AUTOSAR XML (schema 4-0-3)
standard types defined: uint8, Boolean, UInt16, UInt32, UInt8
package /AUTOSAR_Platform/DataConstrs
  range DC_Boolean: raw 0..1
  range DC_UInt16: raw 0..65535
  range DC_UInt8: raw 0..255
package /PATAC/Facility/DataTypes/Implementation
  compu method COMPU_Boolean: 0=FALSE, 1=TRUE
  unit NoUnit: factor-si-to-unit=1, offset-si-to-unit=0
package /PATAC/MSM/ComponentTypes
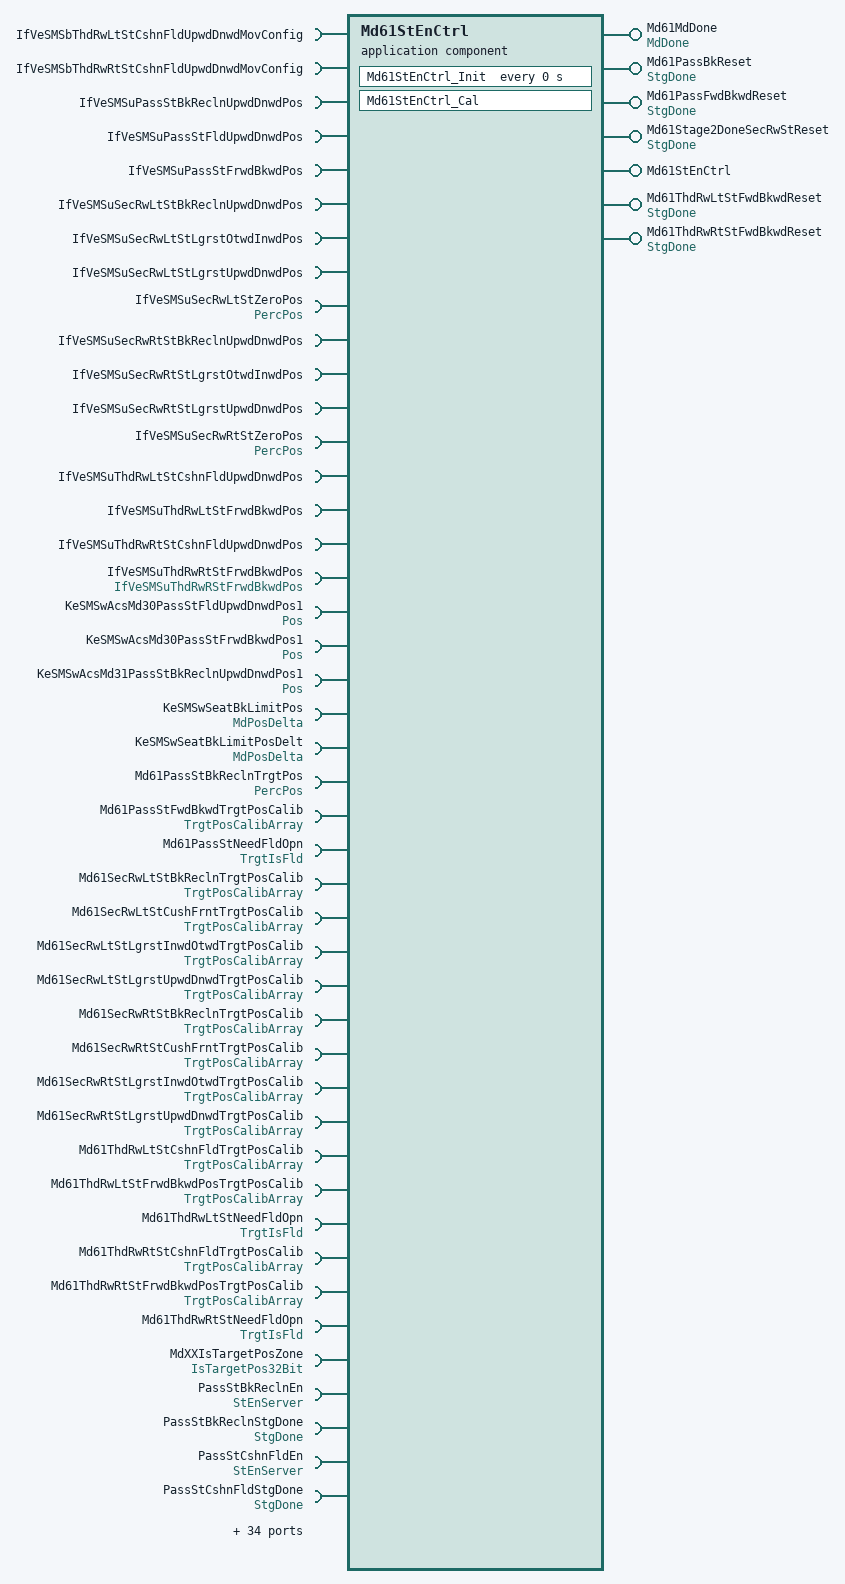
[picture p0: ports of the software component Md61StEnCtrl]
  application sw component type Md61StEnCtrl
    7 x provide port:
      Md61MdDone: nonqueued-sender-com-spec{data-element=MdDone/Val, init-value=0}, provided-interface=MdDone
      Md61PassBkReset: nonqueued-sender-com-spec{data-element=StgDone/Val, init-value=0}, provided-interface=StgDone
      Md61PassFwdBkwdReset: nonqueued-sender-com-spec{data-element=StgDone/Val, init-value=0}, provided-interface=StgDone
      Md61Stage2DoneSecRwStReset: nonqueued-sender-com-spec{data-element=StgDone/Val, init-value=0}, provided-interface=StgDone
      Md61StEnCtrl: server-com-spec{operation=Cal, queue-length=1}, provided-interface=Md61StEnCtrl
      Md61ThdRwLtStFwdBkwdReset: nonqueued-sender-com-spec{data-element=StgDone/Val, init-value=0}, provided-interface=StgDone
      Md61ThdRwRtStFwdBkwdReset: nonqueued-sender-com-spec{data-element=StgDone/Val, init-value=0}, provided-interface=StgDone
    78 x require port:
      IfVeSMSbThdRwLtStCshnFldUpwdDnwdMovConfig: nonqueued-receiver-com-spec{data-element=IfVeSMSbThdRwLtStCshnFldUpwdDnwdMovConfig/Val, filter=data-filter-type=ALWAYS, init-value=0}, required-interface=IfVeSMSbThdRwLtStCshnFldUpwdDnwdMovConfig
      IfVeSMSbThdRwRtStCshnFldUpwdDnwdMovConfig: nonqueued-receiver-com-spec{data-element=IfVeSMSbThdRwRtStCshnFldUpwdDnwdMovConfig/Val, filter=data-filter-type=ALWAYS, init-value=0}, required-interface=IfVeSMSbThdRwRtStCshnFldUpwdDnwdMovConfig
      IfVeSMSuPassStBkReclnUpwdDnwdPos: nonqueued-receiver-com-spec{data-element=IfVeSMSuPassStBkReclnUpwdDnwdPos/Val, filter=data-filter-type=ALWAYS, init-value=0}, required-interface=IfVeSMSuPassStBkReclnUpwdDnwdPos
      IfVeSMSuPassStFldUpwdDnwdPos: nonqueued-receiver-com-spec{data-element=IfVeSMSuPassStFldUpwdDnwdPos/Val, filter=data-filter-type=ALWAYS, init-value=0}, required-interface=IfVeSMSuPassStFldUpwdDnwdPos
      IfVeSMSuPassStFrwdBkwdPos: nonqueued-receiver-com-spec{data-element=IfVeSMSuPassStFrwdBkwdPos/Val, filter=data-filter-type=ALWAYS, init-value=0}, required-interface=IfVeSMSuPassStFrwdBkwdPos
      IfVeSMSuSecRwLtStBkReclnUpwdDnwdPos: nonqueued-receiver-com-spec{data-element=IfVeSMSuSecRwLtStBkReclnUpwdDnwdPos/Val, filter=data-filter-type=ALWAYS, init-value=0}, required-interface=IfVeSMSuSecRwLtStBkReclnUpwdDnwdPos
      IfVeSMSuSecRwLtStLgrstOtwdInwdPos: nonqueued-receiver-com-spec{data-element=IfVeSMSuSecRwLtStLgrstOtwdInwdPos/Val, filter=data-filter-type=ALWAYS, init-value=0}, required-interface=IfVeSMSuSecRwLtStLgrstOtwdInwdPos
      IfVeSMSuSecRwLtStLgrstUpwdDnwdPos: nonqueued-receiver-com-spec{data-element=IfVeSMSuSecRwLtStLgrstUpwdDnwdPos/Val, filter=data-filter-type=ALWAYS, init-value=0}, required-interface=IfVeSMSuSecRwLtStLgrstUpwdDnwdPos
      IfVeSMSuSecRwLtStZeroPos: nonqueued-receiver-com-spec{data-element=PercPos/Val, filter=data-filter-type=ALWAYS, init-value=0}, required-interface=PercPos
      IfVeSMSuSecRwRtStBkReclnUpwdDnwdPos: nonqueued-receiver-com-spec{data-element=IfVeSMSuSecRwRtStBkReclnUpwdDnwdPos/Val, filter=data-filter-type=ALWAYS, init-value=0}, required-interface=IfVeSMSuSecRwRtStBkReclnUpwdDnwdPos
      IfVeSMSuSecRwRtStLgrstOtwdInwdPos: nonqueued-receiver-com-spec{data-element=IfVeSMSuSecRwRtStLgrstOtwdInwdPos/Val, filter=data-filter-type=ALWAYS, init-value=0}, required-interface=IfVeSMSuSecRwRtStLgrstOtwdInwdPos
      IfVeSMSuSecRwRtStLgrstUpwdDnwdPos: nonqueued-receiver-com-spec{data-element=IfVeSMSuSecRwRtStLgrstUpwdDnwdPos/Val, filter=data-filter-type=ALWAYS, init-value=0}, required-interface=IfVeSMSuSecRwRtStLgrstUpwdDnwdPos
      IfVeSMSuSecRwRtStZeroPos: nonqueued-receiver-com-spec{data-element=PercPos/Val, filter=data-filter-type=ALWAYS, init-value=0}, required-interface=PercPos
      IfVeSMSuThdRwLtStCshnFldUpwdDnwdPos: nonqueued-receiver-com-spec{data-element=IfVeSMSuThdRwLtStCshnFldUpwdDnwdPos/Val, filter=data-filter-type=ALWAYS, init-value=0}, required-interface=IfVeSMSuThdRwLtStCshnFldUpwdDnwdPos
      IfVeSMSuThdRwLtStFrwdBkwdPos: nonqueued-receiver-com-spec{data-element=IfVeSMSuThdRwLtStFrwdBkwdPos/Val, filter=data-filter-type=ALWAYS, init-value=0}, required-interface=IfVeSMSuThdRwLtStFrwdBkwdPos
      IfVeSMSuThdRwRtStCshnFldUpwdDnwdPos: nonqueued-receiver-com-spec{data-element=IfVeSMSuThdRwRtStCshnFldUpwdDnwdPos/Val, filter=data-filter-type=ALWAYS, init-value=0}, required-interface=IfVeSMSuThdRwRtStCshnFldUpwdDnwdPos
      IfVeSMSuThdRwRtStFrwdBkwdPos: nonqueued-receiver-com-spec{data-element=IfVeSMSuThdRwRStFrwdBkwdPos/Val, filter=data-filter-type=ALWAYS, init-value=0}, required-interface=IfVeSMSuThdRwRStFrwdBkwdPos
      KeSMSwAcsMd30PassStFldUpwdDnwdPos1: parameter-require-com-spec{init-value=0, parameter=Pos/Val}, required-interface=Pos
      KeSMSwAcsMd30PassStFrwdBkwdPos1: parameter-require-com-spec{init-value=0, parameter=Pos/Val}, required-interface=Pos
      KeSMSwAcsMd31PassStBkReclnUpwdDnwdPos1: parameter-require-com-spec{init-value=0, parameter=Pos/Val}, required-interface=Pos
      KeSMSwSeatBkLimitPos: parameter-require-com-spec{init-value=2052, parameter=MdPosDelta/Val}, required-interface=MdPosDelta
      KeSMSwSeatBkLimitPosDelt: parameter-require-com-spec{init-value=120, parameter=MdPosDelta/Val}, required-interface=MdPosDelta
      Md61PassStBkReclnTrgtPos: nonqueued-receiver-com-spec{data-element=PercPos/Val, filter=data-filter-type=ALWAYS, init-value=0}, required-interface=PercPos
      Md61PassStFwdBkwdTrgtPosCalib: nonqueued-receiver-com-spec{data-element=TrgtPosArray, filter=data-filter-type=ALWAYS, init-value=[4095, 4095, 4095]}, required-interface=TrgtPosCalibArray
      Md61PassStNeedFldOpn: nonqueued-receiver-com-spec{data-element=TrgtIsFld/Val, filter=data-filter-type=ALWAYS, init-value=0}, required-interface=TrgtIsFld
      Md61SecRwLtStBkReclnTrgtPosCalib: nonqueued-receiver-com-spec{data-element=TrgtPosArray, filter=data-filter-type=ALWAYS, init-value=[4095, 4095, 4095]}, required-interface=TrgtPosCalibArray
      Md61SecRwLtStCushFrntTrgtPosCalib: nonqueued-receiver-com-spec{data-element=TrgtPosArray, filter=data-filter-type=ALWAYS, init-value=[4095, 4095, 4095]}, required-interface=TrgtPosCalibArray
      Md61SecRwLtStLgrstInwdOtwdTrgtPosCalib: nonqueued-receiver-com-spec{data-element=TrgtPosArray, filter=data-filter-type=ALWAYS, init-value=[4095, 4095, 4095]}, required-interface=TrgtPosCalibArray
      Md61SecRwLtStLgrstUpwdDnwdTrgtPosCalib: nonqueued-receiver-com-spec{data-element=TrgtPosArray, filter=data-filter-type=ALWAYS, init-value=[4095, 4095, 4095]}, required-interface=TrgtPosCalibArray
      Md61SecRwRtStBkReclnTrgtPosCalib: nonqueued-receiver-com-spec{data-element=TrgtPosArray, filter=data-filter-type=ALWAYS, init-value=[4095, 4095, 4095]}, required-interface=TrgtPosCalibArray
      Md61SecRwRtStCushFrntTrgtPosCalib: nonqueued-receiver-com-spec{data-element=TrgtPosArray, filter=data-filter-type=ALWAYS, init-value=[4095, 4095, 4095]}, required-interface=TrgtPosCalibArray
      Md61SecRwRtStLgrstInwdOtwdTrgtPosCalib: nonqueued-receiver-com-spec{data-element=TrgtPosArray, filter=data-filter-type=ALWAYS, init-value=[4095, 4095, 4095]}, required-interface=TrgtPosCalibArray
      Md61SecRwRtStLgrstUpwdDnwdTrgtPosCalib: nonqueued-receiver-com-spec{data-element=TrgtPosArray, filter=data-filter-type=ALWAYS, init-value=[4095, 4095, 4095]}, required-interface=TrgtPosCalibArray
      Md61ThdRwLtStCshnFldTrgtPosCalib: nonqueued-receiver-com-spec{data-element=TrgtPosArray, filter=data-filter-type=ALWAYS, init-value=[4095, 4095, 4095]}, required-interface=TrgtPosCalibArray
      Md61ThdRwLtStFrwdBkwdPosTrgtPosCalib: nonqueued-receiver-com-spec{data-element=TrgtPosArray, filter=data-filter-type=ALWAYS, init-value=[4095, 4095, 4095]}, required-interface=TrgtPosCalibArray
      Md61ThdRwLtStNeedFldOpn: nonqueued-receiver-com-spec{data-element=TrgtIsFld/Val, filter=data-filter-type=ALWAYS, init-value=0}, required-interface=TrgtIsFld
      Md61ThdRwRtStCshnFldTrgtPosCalib: nonqueued-receiver-com-spec{data-element=TrgtPosArray, filter=data-filter-type=ALWAYS, init-value=[4095, 4095, 4095]}, required-interface=TrgtPosCalibArray
      Md61ThdRwRtStFrwdBkwdPosTrgtPosCalib: nonqueued-receiver-com-spec{data-element=TrgtPosArray, filter=data-filter-type=ALWAYS, init-value=[4095, 4095, 4095]}, required-interface=TrgtPosCalibArray
      Md61ThdRwRtStNeedFldOpn: nonqueued-receiver-com-spec{data-element=TrgtIsFld/Val, filter=data-filter-type=ALWAYS, init-value=0}, required-interface=TrgtIsFld
      MdXXIsTargetPosZone: nonqueued-receiver-com-spec{data-element=IsTargetPos32Bit/Val, filter=data-filter-type=ALWAYS, init-value=0}, required-interface=IsTargetPos32Bit
      PassStBkReclnEn: required-com-specs=[Clear, Get, Set], required-interface=StEnServer
      PassStBkReclnStgDone: nonqueued-receiver-com-spec{data-element=StgDone/Val, filter=data-filter-type=ALWAYS, init-value=0}, required-interface=StgDone
      PassStCshnFldEn: required-com-specs=[Clear, Get, Set], required-interface=StEnServer
      PassStCshnFldStgDone: nonqueued-receiver-com-spec{data-element=StgDone/Val, filter=data-filter-type=ALWAYS, init-value=0}, required-interface=StgDone
      PassStFwdBkwdEn: required-com-specs=[Clear, Get, Set], required-interface=StEnServer
      PassStFwdBkwdStgDone: nonqueued-receiver-com-spec{data-element=StgDone/Val, filter=data-filter-type=ALWAYS, init-value=0}, required-interface=StgDone
      SecRwLtStBkReclnEn: required-com-specs=[Clear, Get, Set], required-interface=StEnServer
      SecRwLtStBkReclnStgDone: nonqueued-receiver-com-spec{data-element=StgDone/Val, filter=data-filter-type=ALWAYS, init-value=0}, required-interface=StgDone
      SecRwLtStFrwdBkwdStgDone: nonqueued-receiver-com-spec{data-element=StgDone/Val, filter=data-filter-type=ALWAYS, init-value=0}, required-interface=StgDone
      SecRwLtStFwdBkwdEn: required-com-specs=[Clear, Get, Set], required-interface=StEnServer
      SecRwLtStLgrstInwdOtwdEn: required-com-specs=[Clear, Get, Set], required-interface=StEnServer
      SecRwLtStLgrstOtwdInwdStgDone: nonqueued-receiver-com-spec{data-element=StgDone/Val, filter=data-filter-type=ALWAYS, init-value=0}, required-interface=StgDone
      SecRwLtStLgrstUpwdDnwdEn: required-com-specs=[Clear, Get, Set], required-interface=StEnServer
      SecRwLtStLgrstUpwdDnwdStgDone: nonqueued-receiver-com-spec{data-element=StgDone/Val, filter=data-filter-type=ALWAYS, init-value=0}, required-interface=StgDone
      SecRwRtStBkReclnEn: required-com-specs=[Clear, Get, Set], required-interface=StEnServer
      SecRwRtStBkReclnStgDone: nonqueued-receiver-com-spec{data-element=StgDone/Val, filter=data-filter-type=ALWAYS, init-value=0}, required-interface=StgDone
      SecRwRtStFrwdBkwdStgDone: nonqueued-receiver-com-spec{data-element=StgDone/Val, filter=data-filter-type=ALWAYS, init-value=0}, required-interface=StgDone
      SecRwRtStFwdBkwdEn: required-com-specs=[Clear, Get, Set], required-interface=StEnServer
      SecRwRtStLgrstInwdOtwdEn: required-com-specs=[Clear, Get, Set], required-interface=StEnServer
      SecRwRtStLgrstOtwdInwdStgDone: nonqueued-receiver-com-spec{data-element=StgDone/Val, filter=data-filter-type=ALWAYS, init-value=0}, required-interface=StgDone
      SecRwRtStLgrstUpwdDnwdEn: required-com-specs=[Clear, Get, Set], required-interface=StEnServer
      SecRwRtStLgrstUpwdDnwdStgDone: nonqueued-receiver-com-spec{data-element=StgDone/Val, filter=data-filter-type=ALWAYS, init-value=0}, required-interface=StgDone
      ThdRwLtStBkReclnEn: required-com-specs=[Clear, Get, Set], required-interface=StEnServer
      ThdRwLtStBkReclnStgDone: nonqueued-receiver-com-spec{data-element=StgDone/Val, filter=data-filter-type=ALWAYS, init-value=0}, required-interface=StgDone
      ThdRwLtStCshnFldEn: required-com-specs=[Clear, Get, Set], required-interface=StEnServer
      ThdRwLtStCshnFldStgDone: nonqueued-receiver-com-spec{data-element=StgDone/Val, filter=data-filter-type=ALWAYS, init-value=0}, required-interface=StgDone
      ThdRwLtStFwdBkwdEn: required-com-specs=[Clear, Get, Set], required-interface=StEnServer
      ThdRwLtStFwdBkwdStgDone: nonqueued-receiver-com-spec{data-element=StgDone/Val, filter=data-filter-type=ALWAYS, init-value=0}, required-interface=StgDone
      ThdRwRtStBkReclnEn: required-com-specs=[Clear, Get, Set], required-interface=StEnServer
      ThdRwRtStBkReclnStgDone: nonqueued-receiver-com-spec{data-element=StgDone/Val, filter=data-filter-type=ALWAYS, init-value=0}, required-interface=StgDone
      ThdRwRtStCshnFldEn: required-com-specs=[Clear, Get, Set], required-interface=StEnServer
      ThdRwRtStCshnFldStgDone: nonqueued-receiver-com-spec{data-element=StgDone/Val, filter=data-filter-type=ALWAYS, init-value=0}, required-interface=StgDone
      ThdRwRtStFwdBkwdEn: required-com-specs=[Clear, Get, Set], required-interface=StEnServer
      ThdRwRtStFwdBkwdStgDone: nonqueued-receiver-com-spec{data-element=StgDone/Val, filter=data-filter-type=ALWAYS, init-value=0}, required-interface=StgDone
      ZeroLEn: required-com-specs=[Clear, Get, Set], required-interface=StEnServer
      ZeroLStgDone: nonqueued-receiver-com-spec{data-element=StgDone/Val, filter=data-filter-type=ALWAYS, init-value=0}, required-interface=StgDone
      ZeroREn: required-com-specs=[Clear, Get, Set], required-interface=StEnServer
      ZeroRStgDone: nonqueued-receiver-com-spec{data-element=StgDone/Val, filter=data-filter-type=ALWAYS, init-value=0}, required-interface=StgDone
    behavior Md61StEnCtrl_InternalBehavior
      operation invoked event OIT_Md61StEnCtrl_Cal_Md61StEnCtrl_Cal: start-on-event=Md61StEnCtrl_Cal, operation=Md61StEnCtrl.Cal
      timing event Md61StEnCtrl_InitEvent: start-on-event=Md61StEnCtrl_Init, period=0
      runnable Md61StEnCtrl_Cal
        data-receive-point-by-arguments:
          54 x access:
            REC_IfVeSMSbThdRwLtStCshnFldUpwdDnwdMovConfig_Val: accessed-variable=IfVeSMSbThdRwLtStCshnFldUpwdDnwdMovConfig.Val
            REC_IfVeSMSbThdRwRtStCshnFldUpwdDnwdMovConfig_Val: accessed-variable=IfVeSMSbThdRwRtStCshnFldUpwdDnwdMovConfig.Val
            REC_IfVeSMSuPassStBkReclnUpwdDnwdPos_Val: accessed-variable=IfVeSMSuPassStBkReclnUpwdDnwdPos.Val
            REC_IfVeSMSuPassStFldUpwdDnwdPos_Val: accessed-variable=IfVeSMSuPassStFldUpwdDnwdPos.Val
            REC_IfVeSMSuPassStFrwdBkwdPos_Val: accessed-variable=IfVeSMSuPassStFrwdBkwdPos.Val
            REC_IfVeSMSuSecRwLtStBkReclnUpwdDnwdPos_Val: accessed-variable=IfVeSMSuSecRwLtStBkReclnUpwdDnwdPos.Val
            REC_IfVeSMSuSecRwLtStLgrstOtwdInwdPos_Val: accessed-variable=IfVeSMSuSecRwLtStLgrstOtwdInwdPos.Val
            REC_IfVeSMSuSecRwLtStLgrstUpwdDnwdPos_Val: accessed-variable=IfVeSMSuSecRwLtStLgrstUpwdDnwdPos.Val
            REC_IfVeSMSuSecRwLtStZeroPos_Val: accessed-variable=IfVeSMSuSecRwLtStZeroPos.Val
            REC_IfVeSMSuSecRwRtStBkReclnUpwdDnwdPos_Val: accessed-variable=IfVeSMSuSecRwRtStBkReclnUpwdDnwdPos.Val
            REC_IfVeSMSuSecRwRtStLgrstOtwdInwdPos_Val: accessed-variable=IfVeSMSuSecRwRtStLgrstOtwdInwdPos.Val
            REC_IfVeSMSuSecRwRtStLgrstUpwdDnwdPos_Val: accessed-variable=IfVeSMSuSecRwRtStLgrstUpwdDnwdPos.Val
            REC_IfVeSMSuSecRwRtStZeroPos_Val: accessed-variable=IfVeSMSuSecRwRtStZeroPos.Val
            REC_IfVeSMSuThdRwLtStCshnFldUpwdDnwdPos_Val: accessed-variable=IfVeSMSuThdRwLtStCshnFldUpwdDnwdPos.Val
            REC_IfVeSMSuThdRwLtStFrwdBkwdPos_Val: accessed-variable=IfVeSMSuThdRwLtStFrwdBkwdPos.Val
            REC_IfVeSMSuThdRwRtStCshnFldUpwdDnwdPos_Val: accessed-variable=IfVeSMSuThdRwRtStCshnFldUpwdDnwdPos.Val
            REC_IfVeSMSuThdRwRtStFrwdBkwdPos_Val: accessed-variable=IfVeSMSuThdRwRtStFrwdBkwdPos.Val
            REC_Md61PassStBkReclnTrgtPos_Val: accessed-variable=Md61PassStBkReclnTrgtPos.Val
            REC_Md61PassStFwdBkwdTrgtPosCalib_TrgtPosArray: accessed-variable=Md61PassStFwdBkwdTrgtPosCalib.TrgtPosArray
            REC_Md61PassStNeedFldOpn_Val: accessed-variable=Md61PassStNeedFldOpn.Val
            REC_Md61SecRwLtStBkReclnTrgtPosCalib_TrgtPosArray: accessed-variable=Md61SecRwLtStBkReclnTrgtPosCalib.TrgtPosArray
            REC_Md61SecRwLtStCushFrntTrgtPosCalib_TrgtPosArray: accessed-variable=Md61SecRwLtStCushFrntTrgtPosCalib.TrgtPosArray
            REC_Md61SecRwLtStLgrstInwdOtwdTrgtPosCalib_TrgtPosArray: accessed-variable=Md61SecRwLtStLgrstInwdOtwdTrgtPosCalib.TrgtPosArray
            REC_Md61SecRwLtStLgrstUpwdDnwdTrgtPosCalib_TrgtPosArray: accessed-variable=Md61SecRwLtStLgrstUpwdDnwdTrgtPosCalib.TrgtPosArray
            REC_Md61SecRwRtStBkReclnTrgtPosCalib_TrgtPosArray: accessed-variable=Md61SecRwRtStBkReclnTrgtPosCalib.TrgtPosArray
            REC_Md61SecRwRtStCushFrntTrgtPosCalib_TrgtPosArray: accessed-variable=Md61SecRwRtStCushFrntTrgtPosCalib.TrgtPosArray
            REC_Md61SecRwRtStLgrstInwdOtwdTrgtPosCalib_TrgtPosArray: accessed-variable=Md61SecRwRtStLgrstInwdOtwdTrgtPosCalib.TrgtPosArray
            REC_Md61SecRwRtStLgrstUpwdDnwdTrgtPosCalib_TrgtPosArray: accessed-variable=Md61SecRwRtStLgrstUpwdDnwdTrgtPosCalib.TrgtPosArray
            REC_Md61ThdRwLtStCshnFldTrgtPosCalib_TrgtPosArray: accessed-variable=Md61ThdRwLtStCshnFldTrgtPosCalib.TrgtPosArray
            REC_Md61ThdRwLtStFrwdBkwdPosTrgtPosCalib_TrgtPosArray: accessed-variable=Md61ThdRwLtStFrwdBkwdPosTrgtPosCalib.TrgtPosArray
            REC_Md61ThdRwLtStNeedFldOpn_Val: accessed-variable=Md61ThdRwLtStNeedFldOpn.Val
            REC_Md61ThdRwRtStCshnFldTrgtPosCalib_TrgtPosArray: accessed-variable=Md61ThdRwRtStCshnFldTrgtPosCalib.TrgtPosArray
            REC_Md61ThdRwRtStFrwdBkwdPosTrgtPosCalib_TrgtPosArray: accessed-variable=Md61ThdRwRtStFrwdBkwdPosTrgtPosCalib.TrgtPosArray
            REC_Md61ThdRwRtStNeedFldOpn_Val: accessed-variable=Md61ThdRwRtStNeedFldOpn.Val
            REC_MdXXIsTargetPosZone_Val: accessed-variable=MdXXIsTargetPosZone.Val
            REC_PassStBkReclnStgDone_Val: accessed-variable=PassStBkReclnStgDone.Val
            REC_PassStCshnFldStgDone_Val: accessed-variable=PassStCshnFldStgDone.Val
            REC_PassStFwdBkwdStgDone_Val: accessed-variable=PassStFwdBkwdStgDone.Val
            REC_SecRwLtStBkReclnStgDone_Val: accessed-variable=SecRwLtStBkReclnStgDone.Val
            REC_SecRwLtStFrwdBkwdStgDone_Val: accessed-variable=SecRwLtStFrwdBkwdStgDone.Val
            REC_SecRwLtStLgrstOtwdInwdStgDone_Val: accessed-variable=SecRwLtStLgrstOtwdInwdStgDone.Val
            REC_SecRwLtStLgrstUpwdDnwdStgDone_Val: accessed-variable=SecRwLtStLgrstUpwdDnwdStgDone.Val
            REC_SecRwRtStBkReclnStgDone_Val: accessed-variable=SecRwRtStBkReclnStgDone.Val
            REC_SecRwRtStFrwdBkwdStgDone_Val: accessed-variable=SecRwRtStFrwdBkwdStgDone.Val
            REC_SecRwRtStLgrstOtwdInwdStgDone_Val: accessed-variable=SecRwRtStLgrstOtwdInwdStgDone.Val
            REC_SecRwRtStLgrstUpwdDnwdStgDone_Val: accessed-variable=SecRwRtStLgrstUpwdDnwdStgDone.Val
            REC_ThdRwLtStBkReclnStgDone_Val: accessed-variable=ThdRwLtStBkReclnStgDone.Val
            REC_ThdRwLtStCshnFldStgDone_Val: accessed-variable=ThdRwLtStCshnFldStgDone.Val
            REC_ThdRwLtStFwdBkwdStgDone_Val: accessed-variable=ThdRwLtStFwdBkwdStgDone.Val
            REC_ThdRwRtStBkReclnStgDone_Val: accessed-variable=ThdRwRtStBkReclnStgDone.Val
            REC_ThdRwRtStCshnFldStgDone_Val: accessed-variable=ThdRwRtStCshnFldStgDone.Val
            REC_ThdRwRtStFwdBkwdStgDone_Val: accessed-variable=ThdRwRtStFwdBkwdStgDone.Val
            REC_ZeroLStgDone_Val: accessed-variable=ZeroLStgDone.Val
            REC_ZeroRStgDone_Val: accessed-variable=ZeroRStgDone.Val
        data-send-points:
          6 x access:
            SEND_Md61MdDone_Val: accessed-variable=Md61MdDone.Val
            SEND_Md61PassBkReset_Val: accessed-variable=Md61PassBkReset.Val
            SEND_Md61PassFwdBkwdReset_Val: accessed-variable=Md61PassFwdBkwdReset.Val
            SEND_Md61Stage2DoneSecRwStReset_Val: accessed-variable=Md61Stage2DoneSecRwStReset.Val
            SEND_Md61ThdRwLtStFwdBkwdReset_Val: accessed-variable=Md61ThdRwLtStFwdBkwdReset.Val
            SEND_Md61ThdRwRtStFwdBkwdReset_Val: accessed-variable=Md61ThdRwRtStFwdBkwdReset.Val
        5 x parameter access:
          PA_KeSMSwAcsMd30PassStFldUpwdDnwdPos1_Val: accessed-parameter=KeSMSwAcsMd30PassStFldUpwdDnwdPos1.Val
          PA_KeSMSwAcsMd30PassStFrwdBkwdPos1_Val: accessed-parameter=KeSMSwAcsMd30PassStFrwdBkwdPos1.Val
          PA_KeSMSwAcsMd31PassStBkReclnUpwdDnwdPos1_Val: accessed-parameter=KeSMSwAcsMd31PassStBkReclnUpwdDnwdPos1.Val
          PA_KeSMSwSeatBkLimitPos_Val: accessed-parameter=KeSMSwSeatBkLimitPos.Val
          PA_KeSMSwSeatBkLimitPosDelt_Val: accessed-parameter=KeSMSwSeatBkLimitPosDelt.Val
        38 x sync call, all with timeout=0:
          SC_PassStBkReclnEn_Clear: operation=PassStBkReclnEn.Clear
          SC_PassStBkReclnEn_Set: operation=PassStBkReclnEn.Set
          SC_PassStCshnFldEn_Clear: operation=PassStCshnFldEn.Clear
          SC_PassStCshnFldEn_Set: operation=PassStCshnFldEn.Set
          SC_PassStFwdBkwdEn_Clear: operation=PassStFwdBkwdEn.Clear
          SC_PassStFwdBkwdEn_Set: operation=PassStFwdBkwdEn.Set
          SC_SecRwLtStBkReclnEn_Clear: operation=SecRwLtStBkReclnEn.Clear
          SC_SecRwLtStBkReclnEn_Set: operation=SecRwLtStBkReclnEn.Set
          SC_SecRwLtStFwdBkwdEn_Clear: operation=SecRwLtStFwdBkwdEn.Clear
          SC_SecRwLtStFwdBkwdEn_Set: operation=SecRwLtStFwdBkwdEn.Set
          SC_SecRwLtStLgrstInwdOtwdEn_Clear: operation=SecRwLtStLgrstInwdOtwdEn.Clear
          SC_SecRwLtStLgrstInwdOtwdEn_Set: operation=SecRwLtStLgrstInwdOtwdEn.Set
          SC_SecRwLtStLgrstUpwdDnwdEn_Clear: operation=SecRwLtStLgrstUpwdDnwdEn.Clear
          SC_SecRwLtStLgrstUpwdDnwdEn_Set: operation=SecRwLtStLgrstUpwdDnwdEn.Set
          SC_SecRwRtStBkReclnEn_Clear: operation=SecRwRtStBkReclnEn.Clear
          SC_SecRwRtStBkReclnEn_Set: operation=SecRwRtStBkReclnEn.Set
          SC_SecRwRtStFwdBkwdEn_Clear: operation=SecRwRtStFwdBkwdEn.Clear
          SC_SecRwRtStFwdBkwdEn_Set: operation=SecRwRtStFwdBkwdEn.Set
          SC_SecRwRtStLgrstInwdOtwdEn_Clear: operation=SecRwRtStLgrstInwdOtwdEn.Clear
          SC_SecRwRtStLgrstInwdOtwdEn_Set: operation=SecRwRtStLgrstInwdOtwdEn.Set
          SC_SecRwRtStLgrstUpwdDnwdEn_Clear: operation=SecRwRtStLgrstUpwdDnwdEn.Clear
          SC_SecRwRtStLgrstUpwdDnwdEn_Set: operation=SecRwRtStLgrstUpwdDnwdEn.Set
          SC_ThdRwLtStBkReclnEn_Clear: operation=ThdRwLtStBkReclnEn.Clear
          SC_ThdRwLtStBkReclnEn_Set: operation=ThdRwLtStBkReclnEn.Set
          SC_ThdRwLtStCshnFldEn_Clear: operation=ThdRwLtStCshnFldEn.Clear
          SC_ThdRwLtStCshnFldEn_Set: operation=ThdRwLtStCshnFldEn.Set
          SC_ThdRwLtStFwdBkwdEn_Clear: operation=ThdRwLtStFwdBkwdEn.Clear
          SC_ThdRwLtStFwdBkwdEn_Set: operation=ThdRwLtStFwdBkwdEn.Set
          SC_ThdRwRtStBkReclnEn_Clear: operation=ThdRwRtStBkReclnEn.Clear
          SC_ThdRwRtStBkReclnEn_Set: operation=ThdRwRtStBkReclnEn.Set
          SC_ThdRwRtStCshnFldEn_Clear: operation=ThdRwRtStCshnFldEn.Clear
          SC_ThdRwRtStCshnFldEn_Set: operation=ThdRwRtStCshnFldEn.Set
          SC_ThdRwRtStFwdBkwdEn_Clear: operation=ThdRwRtStFwdBkwdEn.Clear
          SC_ThdRwRtStFwdBkwdEn_Set: operation=ThdRwRtStFwdBkwdEn.Set
          SC_ZeroLEn_Clear: operation=ZeroLEn.Clear
          SC_ZeroLEn_Set: operation=ZeroLEn.Set
          SC_ZeroREn_Clear: operation=ZeroREn.Clear
          SC_ZeroREn_Set: operation=ZeroREn.Set
      runnable Md61StEnCtrl_Init
        5 x parameter access:
          PA_KeSMSwAcsMd30PassStFldUpwdDnwdPos1_Val: accessed-parameter=KeSMSwAcsMd30PassStFldUpwdDnwdPos1.Val
          PA_KeSMSwAcsMd30PassStFrwdBkwdPos1_Val: accessed-parameter=KeSMSwAcsMd30PassStFrwdBkwdPos1.Val
          PA_KeSMSwAcsMd31PassStBkReclnUpwdDnwdPos1_Val: accessed-parameter=KeSMSwAcsMd31PassStBkReclnUpwdDnwdPos1.Val
          PA_KeSMSwSeatBkLimitPos_Val: accessed-parameter=KeSMSwSeatBkLimitPos.Val
          PA_KeSMSwSeatBkLimitPosDelt_Val: accessed-parameter=KeSMSwSeatBkLimitPosDelt.Val
  swc implementation Md61StEnCtrl_Implementation: behavior=Md61StEnCtrl_InternalBehavior
    code-descriptors:
      code Default: artifact-descriptors=autosar-engineering-object={short-label=Default, category=SWSRC}
package /PATAC/MSM/ModeAdjust/CalPortInterface
  parameter interface MdPosDelta
    parameter data prototype Val: sw-calibration-access=READ-WRITE, type=UInt16
  parameter interface Pos
    parameter data prototype Val: sw-calibration-access=READ-WRITE, type=UInt16
package /PATAC/MSM/ModeAdjust/DataType
  impl type TrgtPosCalibArray: category=ARRAY, sw-calibration-access=READ-ONLY, type-emitter=RTE  # 0:pos 1:max 2:min
    element Element: array-size=3, array-size-semantics=FIXED-SIZE, implementation-data-type=UInt16, invalid-value=0
package /PATAC/MSM/ModeAdjust/Interfaces
  sender receiver interface IfVeSMSuThdRwLtStCshnFldUpwdDnwdPos: invalidation-policy{data-element=IfVeSMSuThdRwLtStCshnFldUpwdDnwdPos/Val, handle-invalid=DONT-INVALIDATE}
    data Val: type=UInt16
  sender receiver interface IfVeSMSuThdRwRtStCshnFldUpwdDnwdPos: invalidation-policy{data-element=IfVeSMSuThdRwRtStCshnFldUpwdDnwdPos/Val, handle-invalid=DONT-INVALIDATE}
    data Val: type=UInt16
package /PATAC/MSM/ModeAdjust/PortInterface
  client server interface Md61StEnCtrl
    operation Cal
      arg FirstTrig: type=Boolean, direction=IN, server-argument-impl-policy=USE-ARGUMENT-TYPE
  client server interface StEnServer
    operation Clear
      arg data: type=UInt8, direction=IN, server-argument-impl-policy=USE-ARGUMENT-TYPE
    operation Get
      arg data: type=UInt32, direction=OUT, server-argument-impl-policy=USE-ARGUMENT-TYPE
    operation Set
      arg data: type=UInt8, direction=IN, server-argument-impl-policy=USE-ARGUMENT-TYPE
  7 x sender receiver interface:
    IfVeSMSuPassStFldUpwdDnwdPos: invalidation-policy{data-element=IfVeSMSuPassStFldUpwdDnwdPos/Val, handle-invalid=DONT-INVALIDATE}
      data Val: type=UInt16
    IsTargetPos32Bit: invalidation-policy{data-element=IsTargetPos32Bit/Val, handle-invalid=DONT-INVALIDATE}
      data Val: type=UInt32
    MdDone: invalidation-policy{data-element=MdDone/Val, handle-invalid=DONT-INVALIDATE}
      data Val: type=UInt8
    PercPos: invalidation-policy{data-element=PercPos/Val, handle-invalid=DONT-INVALIDATE}
      data Val: type=UInt16
    StgDone: invalidation-policy{data-element=StgDone/Val, handle-invalid=DONT-INVALIDATE}
      data Val: type=Boolean
    TrgtIsFld: invalidation-policy{data-element=TrgtIsFld/Val, handle-invalid=DONT-INVALIDATE}
      data Val: type=Boolean
    TrgtPosCalibArray: invalidation-policy{data-element=TrgtPosArray, handle-invalid=DONT-INVALIDATE}
      data TrgtPosArray: type=TrgtPosCalibArray  # 0:Pos 1:Max 2:Min
package /PATAC/MSM/PortInterfaces
  12 x sender receiver interface:
    IfVeSMSbThdRwLtStCshnFldUpwdDnwdMovConfig: invalidation-policy{data-element=IfVeSMSbThdRwLtStCshnFldUpwdDnwdMovConfig/Val, handle-invalid=DONT-INVALIDATE}
      data Val: type=Boolean
    IfVeSMSbThdRwRtStCshnFldUpwdDnwdMovConfig: invalidation-policy{data-element=IfVeSMSbThdRwRtStCshnFldUpwdDnwdMovConfig/Val, handle-invalid=DONT-INVALIDATE}
      data Val: type=Boolean
    IfVeSMSuPassStBkReclnUpwdDnwdPos: invalidation-policy{data-element=IfVeSMSuPassStBkReclnUpwdDnwdPos/Val, handle-invalid=DONT-INVALIDATE}
      data Val: type=UInt16
    IfVeSMSuPassStFrwdBkwdPos: invalidation-policy{data-element=IfVeSMSuPassStFrwdBkwdPos/Val, handle-invalid=DONT-INVALIDATE}
      data Val: type=UInt16
    IfVeSMSuSecRwLtStBkReclnUpwdDnwdPos: invalidation-policy{data-element=IfVeSMSuSecRwLtStBkReclnUpwdDnwdPos/Val, handle-invalid=DONT-INVALIDATE}
      data Val: type=UInt16
    IfVeSMSuSecRwLtStLgrstOtwdInwdPos: invalidation-policy{data-element=IfVeSMSuSecRwLtStLgrstOtwdInwdPos/Val, handle-invalid=DONT-INVALIDATE}
      data Val: type=UInt16
    IfVeSMSuSecRwLtStLgrstUpwdDnwdPos: invalidation-policy{data-element=IfVeSMSuSecRwLtStLgrstUpwdDnwdPos/Val, handle-invalid=DONT-INVALIDATE}
      data Val: type=UInt16
    IfVeSMSuSecRwRtStBkReclnUpwdDnwdPos: invalidation-policy{data-element=IfVeSMSuSecRwRtStBkReclnUpwdDnwdPos/Val, handle-invalid=DONT-INVALIDATE}
      data Val: type=UInt16
    IfVeSMSuSecRwRtStLgrstOtwdInwdPos: invalidation-policy{data-element=IfVeSMSuSecRwRtStLgrstOtwdInwdPos/Val, handle-invalid=DONT-INVALIDATE}
      data Val: type=UInt16
    IfVeSMSuSecRwRtStLgrstUpwdDnwdPos: invalidation-policy{data-element=IfVeSMSuSecRwRtStLgrstUpwdDnwdPos/Val, handle-invalid=DONT-INVALIDATE}
      data Val: type=UInt16
    IfVeSMSuThdRwLtStFrwdBkwdPos: invalidation-policy{data-element=IfVeSMSuThdRwLtStFrwdBkwdPos/Val, handle-invalid=DONT-INVALIDATE}
      data Val: type=UInt16
    IfVeSMSuThdRwRStFrwdBkwdPos: invalidation-policy{data-element=IfVeSMSuThdRwRStFrwdBkwdPos/Val, handle-invalid=DONT-INVALIDATE}
      data Val: type=UInt16
